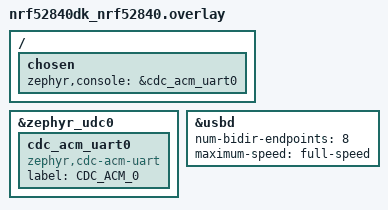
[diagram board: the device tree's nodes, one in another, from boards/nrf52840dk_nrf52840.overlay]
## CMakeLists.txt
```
# SPDX-License-Identifier: Apache-2.0

cmake_minimum_required(VERSION 3.20.0)

find_package(Zephyr REQUIRED HINTS $ENV{ZEPHYR_BASE})
project(usb_printer)

target_sources(app PRIVATE
  src/main.c
  src/printer_pcl.c
  src/printer_pjl.c
  src/printer_queue.c
  )

# Add include directory
target_include_directories(app PRIVATE
  ${CMAKE_CURRENT_SOURCE_DIR}/src
  )

# Generate version header
configure_file(
  ${CMAKE_CURRENT_SOURCE_DIR}/src/version.h.in
  ${CMAKE_CURRENT_BINARY_DIR}/include/generated/version.h
  )
```

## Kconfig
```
# Copyright (c) 2024 Nordic Semiconductor ASA
# SPDX-License-Identifier: Apache-2.0

source "Kconfig.zephyr"

config USB_PRINTER_SAMPLE_DEVICE_ID
	string "IEEE 1284 Device ID string"
	default "MFG:Zephyr;MDL:USB-Printer;CMD:PJL,PCL;CLS:PRINTER;DES:Zephyr USB Printer Sample;VER:1.0;"
	help
	  IEEE 1284 Device ID string reported by the printer.

config USB_PRINTER_SAMPLE_RING_BUF_SIZE
	int "Size of receive ring buffer"
	default 1024
	range 256 4096
	help
	  Size of the ring buffer used for receiving print data.

config USB_PRINTER_SAMPLE_PCL_SUPPORT
	bool "Enable PCL command support"
	default y
	help
	  Enable support for PCL printer commands.

config USB_PRINTER_SAMPLE_PJL_SUPPORT
	bool "Enable PJL job control"
	default y
	depends on USB_PRINTER_SAMPLE_PCL_SUPPORT
	help
	  Enable support for PJL job control commands.

config USB_PRINTER_SAMPLE_TEST_PAGE
	bool "Enable test page support"
	default y
	help
	  Enable built-in test page generation.

config USB_PRINTER_SAMPLE_SIMULATED_ERRORS
	bool "Enable error simulation"
	default y
	help
	  Enable simulated paper out errors for testing.

config USB_PRINTER_SAMPLE_JOB_QUEUE_SIZE
	int "Maximum number of queued print jobs"
	default 5
	range 1 20
	help
	  Maximum number of print jobs that can be queued.
	  Each job requires memory for tracking status.

config USB_PRINTER_SAMPLE_PJL_BUFFER_SIZE
	int "Size of PJL response buffer"
	default 256
	range 128 1024
	depends on USB_PRINTER_SAMPLE_PJL_SUPPORT
	help
	  Size of buffer used for PJL response generation.
```

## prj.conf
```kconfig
# Enable USB
CONFIG_USB_DEVICE_STACK=y
CONFIG_USB_DEVICE_DRIVER=y

# Enable USB Printer class
CONFIG_USB_DEVICE_PRINTER=y

# Sample configs
CONFIG_USB_PRINTER_SAMPLE_DEVICE_ID="MFG:Zephyr;MDL:USB-Printer;CMD:PJL,PCL;CLS:PRINTER;DES:Zephyr USB Printer Sample;VER:1.0;"
CONFIG_USB_PRINTER_SAMPLE_RING_BUF_SIZE=1024
CONFIG_USB_PRINTER_SAMPLE_PJL_BUFFER_SIZE=256
CONFIG_USB_PRINTER_SAMPLE_PCL_SUPPORT=y
CONFIG_USB_PRINTER_SAMPLE_PJL_SUPPORT=y
CONFIG_USB_PRINTER_SAMPLE_TEST_PAGE=y
CONFIG_USB_PRINTER_SAMPLE_JOB_QUEUE_SIZE=5
CONFIG_USB_PRINTER_SAMPLE_SIMULATED_ERRORS=y

# Logging
CONFIG_USB_DRIVER_LOG_LEVEL_INF=y
CONFIG_USB_DEVICE_LOG_LEVEL_INF=y
CONFIG_LOG=y
CONFIG_LOG_DEFAULT_LEVEL=3

# Threading
CONFIG_MULTITHREADING=y
CONFIG_NUM_PREEMPT_PRIORITIES=16
CONFIG_MAIN_STACK_SIZE=2048
CONFIG_HEAP_MEM_POOL_SIZE=4096

# Enable errno defines
CONFIG_ERRNO=y

# System clock configuration
CONFIG_SYS_CLOCK_TICKS_PER_SEC=1000

# Enable USB device stack next generation
CONFIG_USB_DEVICE_STACK_NEXT=y

# Enable USB device string descriptors
CONFIG_USB_DEVICE_STRING_DESC_MAX_LEN=64

# Enable USB composite device support
CONFIG_USB_COMPOSITE_DEVICE=y

# Enable USB device manufacturing string
CONFIG_USB_DEVICE_MANUFACTURER="Zephyr"
CONFIG_USB_DEVICE_PRODUCT="USB Printer"
CONFIG_USB_DEVICE_SN="0123456789AB"
```

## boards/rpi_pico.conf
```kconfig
# Increase USB buffer sizes for Pico
CONFIG_USB_DEVICE_BULK_EP_MPS=64
CONFIG_USB_PRINTER_SAMPLE_RING_BUF_SIZE=2048

# Optimize memory usage
CONFIG_HEAP_MEM_POOL_SIZE=2048
CONFIG_MAIN_STACK_SIZE=2048
CONFIG_USB_DEVICE_STACK_NEXT=y

# Enable USB logging for debugging
CONFIG_USB_DRIVER_LOG_LEVEL_INF=y
CONFIG_USB_DEVICE_LOG_LEVEL_INF=y
```

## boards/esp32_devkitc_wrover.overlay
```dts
/* Enable USB on ESP32-WROVER */

/ {
	chosen {
		zephyr,console = &uart0;
	};
};

&usb_serial {
	status = "okay";
};
```

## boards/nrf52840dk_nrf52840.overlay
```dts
/* Add USB support for nRF52840 DK */

/ {
	chosen {
		zephyr,console = &cdc_acm_uart0;
	};
};

&zephyr_udc0 {
	cdc_acm_uart0: cdc_acm_uart0 {
		compatible = "zephyr,cdc-acm-uart";
		label = "CDC_ACM_0";
	};
};

&usbd {
	status = "okay";
	num-bidir-endpoints = <8>;
	maximum-speed = "full-speed";
};
```

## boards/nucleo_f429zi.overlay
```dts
/* Enable USB on STM32F429 Nucleo */

/ {
	chosen {
		zephyr,console = &usart3;
	};
};

&usb {
	status = "okay";
	pinctrl-0 = <&usb_otg_fs_dm_pa11 &usb_otg_fs_dp_pa12>;
	pinctrl-names = "default";
};

&clk_hse {
	status = "okay";
	clock-frequency = <8000000>;
};
```

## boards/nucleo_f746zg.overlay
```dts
/* Enable USB on STM32 Nucleo boards */

&clk_hse {
    clock-frequency = <DT_FREQ_M(8)>;
    status = "okay";
};

&pll {
    div-m = <8>;
    mul-n = <336>;
    div-p = <2>;
    div-q = <7>;
    clocks = <&clk_hse>;
    status = "okay";
};

&rcc {
    clocks = <&pll>;
    clock-frequency = <DT_FREQ_M(168)>;
    ahb-prescaler = <1>;
    apb1-prescaler = <4>;
    apb2-prescaler = <2>;
};

&usbotg_fs {
    pinctrl-0 = <&usb_otg_fs_dm_pa11 &usb_otg_fs_dp_pa12>;
    pinctrl-names = "default";
    status = "okay";
};
```

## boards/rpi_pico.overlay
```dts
/* Enable USB on Raspberry Pi Pico */

/ {
	chosen {
		zephyr,console = &uart0;
	};
};

&usbd {
	status = "okay";
};

&uart0 {
	status = "okay";
	current-speed = <115200>;
};
```

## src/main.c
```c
/*
 * Copyright (c) 2024 Nordic Semiconductor ASA
 *
 * SPDX-License-Identifier: Apache-2.0
 */

#include <zephyr/kernel.h>
#include <zephyr/device.h>
#include <zephyr/logging/log.h>
#include <zephyr/usb/usb_device.h>
#include <zephyr/usb/class/usb_printer.h>
#include <zephyr/sys/ring_buffer.h>
#include <errno.h>
#include <zephyr/sys/byteorder.h>
#include <string.h>
#include "printer_pcl.h"
#include "printer_pjl.h"
#include "printer_queue.h"

LOG_MODULE_REGISTER(main);

/* Ring buffer for received data */
RING_BUF_DECLARE(printer_rx_buf, CONFIG_USB_PRINTER_SAMPLE_RING_BUF_SIZE);
K_MUTEX_DEFINE(printer_rx_mutex);

/* Semaphore to signal data reception */
K_SEM_DEFINE(printer_rx_sem, 0, 1);

/* Printer state tracking */
static struct pcl_parser_state pcl_parser;
static struct print_job *current_job;
static bool printer_paper_present = true;
static enum printer_state {
    PRINTER_READY,
    PRINTER_BUSY,
    PRINTER_ERROR,
    PRINTER_NO_PAPER
} current_state = PRINTER_READY;

/* PJL response buffer */
static char pjl_response[CONFIG_USB_PRINTER_SAMPLE_PJL_BUFFER_SIZE];

#if defined(CONFIG_USB_PRINTER_SAMPLE_TEST_PAGE)
/* Test page buffer */
static uint8_t test_page[TEST_PAGE_WIDTH * TEST_PAGE_HEIGHT];
static size_t test_page_len;
static bool test_page_pending;
#endif

static void update_printer_status(void)
{
    uint8_t status = USB_PRINTER_STATUS_SELECTED;

    switch (current_state) {
    case PRINTER_ERROR:
        status |= USB_PRINTER_STATUS_ERROR;
        break;
    case PRINTER_NO_PAPER:
        status |= USB_PRINTER_STATUS_ERROR | USB_PRINTER_STATUS_PAPER;
        break;
    default:
        break;
    }

    usb_printer_update_status(status);

    /* Send PJL status update if job active */
    if (current_job) {
        int len = pjl_generate_response(pjl_response, sizeof(pjl_response),
                                      PJL_USTATUS " DEVICE", current_job);
        if (len > 0) {
            usb_printer_send_data(pjl_response, len);
        }
    }
}

/* Job management */
static void start_print_job(void)
{
    if (current_job == NULL) {
        current_job = print_queue_get_next();
        if (current_job) {
            LOG_INF("Processing job %d (%s)", 
                    current_job->job_id, current_job->name);
            update_printer_status();
        }
    }
}

static void finish_current_job(bool success)
{
    if (current_job) {
        uint32_t duration = (k_uptime_get_32() - current_job->start_time) / 1000;
        
        if (success) {
            LOG_INF("Completed job %d (%s): %d pages in %d seconds",
                    current_job->job_id, current_job->name,
                    current_job->pages_printed, duration);
            print_queue_update_state(current_job->job_id,
                                   JOB_STATE_COMPLETED, 0);
        } else {
            LOG_WRN("Failed job %d (%s) after %d pages",
                    current_job->job_id, current_job->name,
                    current_job->pages_printed);
            print_queue_update_state(current_job->job_id,
                                   JOB_STATE_FAILED, current_state);
        }

        /* Send final job status */
        int len = pjl_generate_response(pjl_response, sizeof(pjl_response),
                                      PJL_USTATUS " JOB", current_job);
        if (len > 0) {
            usb_printer_send_data(pjl_response, len);
        }

        current_job = NULL;
        
        /* Clean up completed jobs */
        print_queue_cleanup();
        
        /* Start next job if available */
        start_print_job();
    }
}

#if defined(CONFIG_USB_PRINTER_SAMPLE_SIMULATED_ERRORS)
static void toggle_paper_sensor(void)
{
    printer_paper_present = !printer_paper_present;
    
    if (!printer_paper_present) {
        current_state = PRINTER_NO_PAPER;
        LOG_INF("Paper out");
        
        /* Fail current job if active */
        if (current_job) {
            finish_current_job(false);
        }
    } else {
        current_state = PRINTER_READY;
        LOG_INF("Paper loaded");
        
        /* Start next job if available */
        start_print_job();
    }
    
    update_printer_status();
}
#endif

static void printer_status_changed(bool configured)
{
    if (configured) {
        LOG_INF("USB printer device configured");
        pcl_parser_init(&pcl_parser);
        print_queue_init();
        update_printer_status();
    } else {
        LOG_INF("USB printer device disconnected");
        if (current_job) {
            finish_current_job(false);
        }
        k_mutex_lock(&printer_rx_mutex, K_FOREVER);
        ring_buf_reset(&printer_rx_buf);
        k_mutex_unlock(&printer_rx_mutex);
    }
}

static int printer_class_handle_request(struct usb_setup_packet *setup,
                                      int32_t *len, uint8_t **data)
{
#if defined(CONFIG_USB_PRINTER_SAMPLE_TEST_PAGE)
    /* Check if this is a test page request (vendor-specific) */
    if (setup->bRequest == 0xFF && setup->wValue == 0x00) {
        if (!test_page_pending) {
            struct print_job *job = pcl_start_print_job();
            if (job) {
                strncpy(job->name, "Test Page", sizeof(job->name));
                if (print_queue_add_job(job)) {
                    pcl_generate_test_page(test_page, &test_page_len);
                    test_page_pending = true;
                    start_print_job();
                } else {
                    k_free(job);
                    return -EBUSY;
                }
            }
        }
        return 0;
    }
#endif
    return -ENOTSUP;
}

/* Process received data */
static void process_received_data(const uint8_t *data, size_t len)
{
#if defined(CONFIG_USB_PRINTER_SAMPLE_PJL_SUPPORT)
    /* Check for PJL commands first */
    if (pjl_process_command(current_job, data, len)) {
        /* Generate PJL response if needed */
        int resp_len = pjl_generate_response(pjl_response,
                                           sizeof(pjl_response),
                                           (const char *)data,
                                           current_job);
        if (resp_len > 0) {
            usb_printer_send_data(pjl_response, resp_len);
        }
        return;
    }
#endif

#if defined(CONFIG_USB_PRINTER_SAMPLE_PCL_SUPPORT)
    /* Process PCL if not PJL */
    pcl_process_command(&pcl_parser, current_job, data, len);
#else
    /* Raw text mode - just count form feeds */
    for (size_t i = 0; i < len; i++) {
        if (data[i] == PCL_FF && current_job) {
            current_job->pages_printed++;
            LOG_INF("Page %d printed", current_job->pages_printed);
        }
    }
#endif
}

/* Data received callback */
static void printer_data_received(const uint8_t *data, size_t len)
{
    if (!data || !len) {
        return;
    }

    /* Reject data if we're in an error state */
    if (current_state == PRINTER_ERROR || current_state == PRINTER_NO_PAPER) {
        LOG_WRN("Printer not ready, data rejected");
        return;
    }

    /* Start a new print job if needed */
    if (!current_job) {
        struct print_job *job = pcl_start_print_job();
        if (job) {
            snprintf(job->name, sizeof(job->name),
                    "Job-%d", job->job_id);
            if (print_queue_add_job(job)) {
                start_print_job();
            } else {
                k_free(job);
                return;
            }
        }
    }

    k_mutex_lock(&printer_rx_mutex, K_FOREVER);
    
    uint32_t written = ring_buf_put(&printer_rx_buf, data, len);
    if (written < len) {
        LOG_WRN("Buffer full, dropped %d bytes", len - written);
    }
    
    k_mutex_unlock(&printer_rx_mutex);
    k_sem_give(&printer_rx_sem);
}

/* USB Printer configuration */
static const struct usb_printer_config printer_config = {
    .status_cb = printer_status_changed,
    .class_handler = printer_class_handle_request,
    .device_id = CONFIG_USB_PRINTER_SAMPLE_DEVICE_ID,
    .data_received = printer_data_received,
};

#if defined(CONFIG_USB_PRINTER_SAMPLE_TEST_PAGE)
/* Process test page if pending */
static void process_test_page(void)
{
    if (test_page_pending && current_job) {
        int ret = usb_printer_send_data(test_page, test_page_len);
        if (ret > 0) {
            LOG_INF("Test page sent");
            current_job->pages_printed++;
            finish_current_job(true);
        }
        test_page_pending = false;
    }
}
#endif

/* Print data processing task */
static void printer_task(void)
{
    uint8_t buf[64];
    uint32_t bytes_read;

    while (1) {
        /* Wait for data */
        k_sem_take(&printer_rx_sem, K_FOREVER);

#if defined(CONFIG_USB_PRINTER_SAMPLE_TEST_PAGE)
        /* Process test page if pending */
        process_test_page();
#endif

        k_mutex_lock(&printer_rx_mutex, K_FOREVER);
        bytes_read = ring_buf_get(&printer_rx_buf, buf, sizeof(buf));
        k_mutex_unlock(&printer_rx_mutex);

        if (bytes_read > 0) {
            /* Process received print data */
            LOG_HEXDUMP_DBG(buf, bytes_read, "Received print data:");
            
            /* Simulate busy state during processing */
            current_state = PRINTER_BUSY;
            update_printer_status();
            
            /* Process received data */
            process_received_data(buf, bytes_read);
            
            /* Check if job complete */
            if (current_job && current_job->pages_printed > 0 &&
                ring_buf_is_empty(&printer_rx_buf)) {
                finish_current_job(true);
            }
            
            /* Return to ready if no errors occurred */
            if (current_state == PRINTER_BUSY) {
                current_state = PRINTER_READY;
                update_printer_status();
            }
            
#if defined(CONFIG_USB_PRINTER_SAMPLE_SIMULATED_ERRORS)
            /* Simulate paper out every 10 pages */
            if (current_job && (current_job->pages_printed % 10) == 0) {
                toggle_paper_sensor();
            }
#endif
            
            /* Simulate processing time */
            k_sleep(K_MSEC(100));
        }
    }
}

K_THREAD_DEFINE(printer_task_id, 2048, printer_task, NULL, NULL, NULL,
                K_PRIO_PREEMPT(8), 0, 0);

void main(void)
{
    int ret;

    LOG_INF("Starting USB printer sample");

    ret = usb_printer_init(&printer_config);
    if (ret < 0) {
        LOG_ERR("Failed to initialize USB printer: %d", ret);
        return;
    }

    LOG_INF("USB printer initialized");
}
```

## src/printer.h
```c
#ifndef USB_PRINTER_H
#define USB_PRINTER_H

#include <zephyr/kernel.h>
#include <zephyr/usb/usb_device.h>
#include <zephyr/usb/class/usb_printer.h>

/* Common printer commands */
#define PCL_ESC     0x1B    /* ESC character */
#define PCL_FF      0x0C    /* Form Feed */
#define PCL_LF      0x0A    /* Line Feed */
#define PCL_CR      0x0D    /* Carriage Return */

/* Test page dimensions */
#define TEST_PAGE_WIDTH  80
#define TEST_PAGE_HEIGHT 60

/* Print job states */
enum job_state {
    JOB_STATE_PENDING = 0,
    JOB_STATE_PRINTING,
    JOB_STATE_COMPLETED,
    JOB_STATE_CANCELLED,
    JOB_STATE_FAILED
};

/* Print job structure */
struct print_job {
    uint32_t job_id;
    char name[32];
    enum job_state state;
    uint32_t error_code;
    uint32_t pages_printed;
    uint32_t start_time;
    struct print_job *next;
};

#endif /* USB_PRINTER_H */
```

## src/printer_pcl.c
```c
/*
 * Copyright (c) 2024 Nordic Semiconductor ASA
 *
 * SPDX-License-Identifier: Apache-2.0
 */

#include <zephyr/kernel.h>
#include <string.h>
#include "printer_pcl.h"

#include <zephyr/logging/log.h>
LOG_MODULE_REGISTER(printer_pcl, CONFIG_USB_DEVICE_LOG_LEVEL);

static uint32_t next_job_id;

void pcl_parser_init(struct pcl_parser_state *parser)
{
    memset(parser, 0, sizeof(*parser));
}

#if defined(CONFIG_USB_PRINTER_SAMPLE_PCL_SUPPORT)
static void process_escape_sequence(struct pcl_parser_state *parser,
                                  struct print_job *job)
{
    /* Skip ESC character */
    if (parser->cmd_pos < 2) {
        return;
    }

    switch (parser->cmd_buf[1]) {
    case 'E':  /* Printer reset */
        LOG_INF("PCL: Printer reset");
        parser->landscape = false;
        parser->manual_feed = false;
        break;

    case '&':  /* PCL parameterized command */
        if (parser->cmd_pos < 4) {
            return;
        }
        if (parser->cmd_buf[2] == 'l') {  /* Logical page */
            switch (parser->cmd_buf[3]) {
            case '0':  /* Portrait orientation */
                if (parser->cmd_buf[4] == 'O') {
                    LOG_INF("PCL: Portrait orientation");
                    parser->landscape = false;
                    if (job) {
                        job->landscape = false;
                    }
                }
                break;
            case '1':  /* Landscape orientation */
                if (parser->cmd_buf[4] == 'O') {
                    LOG_INF("PCL: Landscape orientation");
                    parser->landscape = true;
                    if (job) {
                        job->landscape = true;
                    }
                }
                break;
            case '1':  /* Media source - Tray 1 */
                if (parser->cmd_buf[4] == 'H') {
                    LOG_INF("PCL: Paper from Tray 1");
                    parser->manual_feed = false;
                    if (job) {
                        job->manual_feed = false;
                    }
                }
                break;
            case '2':  /* Media source - Manual */
                if (parser->cmd_buf[4] == 'H') {
                    LOG_INF("PCL: Manual paper feed");
                    parser->manual_feed = true;
                    if (job) {
                        job->manual_feed = true;
                    }
                }
                break;
            }
        }
        break;

    case '(':  /* Font selection */
        LOG_INF("PCL: Font selection command");
        break;
    }
}
#endif /* CONFIG_USB_PRINTER_SAMPLE_PCL_SUPPORT */

void pcl_process_command(struct pcl_parser_state *parser,
                        struct print_job *job,
                        const uint8_t *data,
                        size_t len)
{
    for (size_t i = 0; i < len; i++) {
        uint8_t ch = data[i];

#if defined(CONFIG_USB_PRINTER_SAMPLE_PCL_SUPPORT)
        if (parser->in_escape) {
            if (parser->cmd_pos < sizeof(parser->cmd_buf)) {
                parser->cmd_buf[parser->cmd_pos++] = ch;
            }
            /* Look for command terminator */
            if ((ch >= 'A' && ch <= 'Z') || (ch >= 'a' && ch <= 'z')) {
                process_escape_sequence(parser, job);
                parser->in_escape = false;
                parser->cmd_pos = 0;
            }
        } else {
            if (ch == PCL_ESC) {
                parser->in_escape = true;
                parser->cmd_pos = 0;
                parser->cmd_buf[parser->cmd_pos++] = ch;
            } else if (ch == PCL_FF) {
                /* Form feed - page complete */
                if (job) {
                    job->pages_printed++;
                    LOG_INF("Page %d printed", job->pages_printed);
                }
            }
        }
#else
        /* Without PCL support, just count pages on form feeds */
        if (ch == PCL_FF && job) {
            job->pages_printed++;
            LOG_INF("Page %d printed", job->pages_printed);
        }
#endif /* CONFIG_USB_PRINTER_SAMPLE_PCL_SUPPORT */
    }
}

#if defined(CONFIG_USB_PRINTER_SAMPLE_TEST_PAGE)
void pcl_generate_test_page(uint8_t *buffer, size_t *len)
{
    char *pos = buffer;
    int remaining = TEST_PAGE_WIDTH * TEST_PAGE_HEIGHT;

#if defined(CONFIG_USB_PRINTER_SAMPLE_PCL_SUPPORT)
    /* Reset printer and set format with PCL */
    pos += snprintf(pos, remaining, "%s%s%s",
                   PCL_RESET, PCL_PORTRAIT, PCL_FONT_COURIER);
#endif

    /* Header */
    pos += snprintf(pos, remaining,
                   "\r\n\r\n"
                   "    USB Printer Test Page\r\n"
                   "    ===================\r\n\r\n");

    /* Printer information */
    pos += snprintf(pos, remaining,
                   "Model: Virtual PCL Printer\r\n"
                   "Firmware: Zephyr RTOS USB Printer Sample\r\n"
                   "Status: Ready\r\n\r\n");

    /* Print capabilities */
    pos += snprintf(pos, remaining,
                   "Supported Features:\r\n"
#if defined(CONFIG_USB_PRINTER_SAMPLE_PCL_SUPPORT)
                   "- PCL command processing\r\n"
                   "- Portrait/Landscape modes\r\n"
                   "- Multiple paper sources\r\n"
#else
                   "- Raw text printing\r\n"
#endif
                   "- Job tracking\r\n"
                   "- Status reporting\r\n\r\n");

    /* Test patterns */
    pos += snprintf(pos, remaining,
                   "Print Test Pattern:\r\n"
                   "==================\r\n\r\n");

    /* Character test */
    for (char c = 33; c <= 126; c++) {
        *pos++ = c;
        if ((c - 32) % TEST_PAGE_WIDTH == 0) {
            *pos++ = '\r';
            *pos++ = '\n';
        }
    }

    /* Form feed at end of page */
    *pos++ = PCL_FF;

    *len = pos - (char *)buffer;
}
#endif /* CONFIG_USB_PRINTER_SAMPLE_TEST_PAGE */

struct print_job *pcl_start_print_job(void)
{
    struct print_job *job = k_malloc(sizeof(struct print_job));
    
    if (job) {
        memset(job, 0, sizeof(*job));
        job->job_id = ++next_job_id;
        job->start_time = k_uptime_get_32();
    }

    return job;
}
```

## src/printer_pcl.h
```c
/*
 * Copyright (c) 2024 Nordic Semiconductor ASA
 *
 * SPDX-License-Identifier: Apache-2.0
 */

#ifndef PRINTER_PCL_H_
#define PRINTER_PCL_H_

#include <stdint.h>
#include <stdbool.h>
#include <zephyr/kernel.h>

/*
 * PCL Command Reference
 * ====================
 * 
 * Reset:
 * ESC E - Printer reset, clear margins, select default font
 * 
 * Page Control:
 * ESC&l0O - Select portrait orientation
 * ESC&l1O - Select landscape orientation
 * ESC&l1H - Select paper from Tray 1
 * ESC&l2H - Select manual paper feed
 * FF     - Form feed (0x0C)
 * CR     - Carriage return (0x0D)
 * LF     - Line feed (0x0A)
 * 
 * Font Selection:
 * ESC(s#P - Set pitch (# = chars per inch)
 * ESC(s#H - Set height (points)
 * ESC(s#V - Set style (0=upright, 1=italic)
 * ESC(s#S - Set stroke weight (0=normal, 3=bold)
 */

/* PCL command characters */
#define PCL_ESC             0x1B    /* ESC character */
#define PCL_FF              0x0C    /* Form Feed */
#define PCL_CR              0x0D    /* Carriage Return */
#define PCL_LF              0x0A    /* Line Feed */

/* PCL command sequences */
#define PCL_RESET           "\x1BE"
#define PCL_PORTRAIT        "\x1B&l0O"
#define PCL_LANDSCAPE       "\x1B&l1O"
#define PCL_FONT_COURIER    "\x1B(s0p12h0s0b4099T"
#define PCL_FONT_LINE       "\x1B(s1p12v0s0b4099T"
#define PCL_MEDIA_TRAY1     "\x1B&l1H"
#define PCL_MEDIA_MANUAL    "\x1B&l2H"

/* Print job information */
struct print_job {
    uint32_t job_id;
    uint32_t pages_total;
    uint32_t pages_printed;
    bool landscape;
    bool manual_feed;
    uint32_t start_time;
    char name[32];           /* Job name from PJL */
};

/* PCL parser state */
struct pcl_parser_state {
    bool in_escape;
    uint8_t cmd_buf[32];
    uint8_t cmd_pos;
    bool landscape;
    bool manual_feed;
};

/* Test page configuration */
#if defined(CONFIG_USB_PRINTER_SAMPLE_TEST_PAGE)
#define TEST_PAGE_WIDTH     80
#define TEST_PAGE_HEIGHT    60
#endif

/**
 * @brief Initialize PCL parser state
 *
 * @param parser Pointer to parser state structure
 */
void pcl_parser_init(struct pcl_parser_state *parser);

/**
 * @brief Process PCL commands in received data
 *
 * Processes PCL escape sequences and updates printer state.
 * If CONFIG_USB_PRINTER_SAMPLE_PCL_SUPPORT is disabled,
 * treats all data as raw text.
 *
 * @param parser PCL parser state
 * @param job Current print job info
 * @param data Received data buffer
 * @param len Length of received data
 */
void pcl_process_command(struct pcl_parser_state *parser,
                        struct print_job *job,
                        const uint8_t *data,
                        size_t len);

#if defined(CONFIG_USB_PRINTER_SAMPLE_TEST_PAGE)
/**
 * @brief Generate test page content
 *
 * @param buffer Buffer to store test page data
 * @param len Pointer to store length of generated data
 */
void pcl_generate_test_page(uint8_t *buffer, size_t *len);
#endif

/**
 * @brief Start a new print job
 *
 * @return Pointer to new print job structure, or NULL if allocation failed
 */
struct print_job *pcl_start_print_job(void);

#endif /* PRINTER_PCL_H_ */
```

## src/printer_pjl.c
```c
/*
 * Copyright (c) 2024 Nordic Semiconductor ASA
 *
 * SPDX-License-Identifier: Apache-2.0
 */

#include <zephyr/kernel.h>
#include <string.h>
#include "printer_pjl.h"

#include <zephyr/logging/log.h>
LOG_MODULE_REGISTER(printer_pjl, CONFIG_USB_DEVICE_LOG_LEVEL);

/* Command buffer for parsing */
static char cmd_buffer[128];

/* Parse PJL command string */
static const char *pjl_parse_command(const uint8_t *data, size_t len)
{
    /* Look for PJL prefix */
    if (len < strlen(PJL_PREFIX)) {
        return NULL;
    }

    if (memcmp(data, PJL_PREFIX, strlen(PJL_PREFIX)) != 0) {
        return NULL;
    }

    /* Look for @PJL marker */
    const char *cmd = strstr((const char *)data, PJL_ENTER);
    if (!cmd) {
        return NULL;
    }

    /* Skip @PJL and any whitespace */
    cmd += strlen(PJL_ENTER);
    while (*cmd == ' ') {
        cmd++;
    }

    /* Copy command to buffer for parsing */
    strncpy(cmd_buffer, cmd, sizeof(cmd_buffer) - 1);
    cmd_buffer[sizeof(cmd_buffer) - 1] = '\0';

    /* Strip EOL */
    char *eol = strstr(cmd_buffer, PJL_EOL);
    if (eol) {
        *eol = '\0';
    }

    return cmd_buffer;
}

bool pjl_process_command(struct print_job *job,
                        const uint8_t *data,
                        size_t len)
{
    const char *cmd = pjl_parse_command(data, len);
    if (!cmd) {
        return false;
    }

    LOG_DBG("PJL command: %s", cmd);

    if (strncmp(cmd, PJL_JOB, strlen(PJL_JOB)) == 0) {
        /* Job start command */
        if (job) {
            /* Extract job name if present */
            const char *name = strstr(cmd, "NAME=");
            if (name) {
                name += 5; /* Skip "NAME=" */
                if (*name == '"') {
                    name++; /* Skip quote */
                    strncpy(job->name, name, sizeof(job->name) - 1);
                    /* Strip end quote if present */
                    char *quote = strchr(job->name, '"');
                    if (quote) {
                        *quote = '\0';
                    }
                }
            }
            LOG_INF("PJL job start: %s", job->name);
        }
        return true;
    }

    if (strncmp(cmd, PJL_EOJ, strlen(PJL_EOJ)) == 0) {
        /* Job end command */
        if (job) {
            LOG_INF("PJL job end: %s, %d pages", 
                   job->name, job->pages_printed);
        }
        return true;
    }

    if (strncmp(cmd, PJL_ECHO, strlen(PJL_ECHO)) == 0) {
        /* Echo command - will be handled by response generator */
        return true;
    }

    if (strncmp(cmd, PJL_INFO, strlen(PJL_INFO)) == 0) {
        /* Information request - will be handled by response generator */
        return true;
    }

    if (strncmp(cmd, PJL_USTATUS, strlen(PJL_USTATUS)) == 0) {
        /* Status update request - will be handled by response generator */
        return true;
    }

    return false;
}

int pjl_generate_response(char *buffer,
                         size_t size,
                         const char *command,
                         const struct print_job *job)
{
    int len = 0;

    /* Add PJL prefix */
    len += snprintf(buffer + len, size - len, "%s%s", PJL_PREFIX, PJL_EOL);

    if (strncmp(command, PJL_ECHO, strlen(PJL_ECHO)) == 0) {
        /* Echo the command back */
        len += snprintf(buffer + len, size - len, "%s%s", command, PJL_EOL);
    }
    else if (strncmp(command, PJL_INFO, strlen(PJL_INFO)) == 0) {
        /* Return printer information */
        len += snprintf(buffer + len, size - len,
                       "@PJL INFO ID%s"
                       "\"Zephyr USB Printer Sample v1.0\"%s",
                       PJL_EOL, PJL_EOL);
    }
    else if (strncmp(command, PJL_USTATUS, strlen(PJL_USTATUS)) == 0) {
        /* Return printer status */
        if (job) {
            len += snprintf(buffer + len, size - len,
                          "@PJL USTATUS DEVICE%s"
                          "CODE=10001%s"  /* Printer ready */
                          "DISPLAY=\"Ready\"%s"
                          "ONLINE=TRUE%s",
                          PJL_EOL, PJL_EOL, PJL_EOL, PJL_EOL);
        } else {
            len += snprintf(buffer + len, size - len,
                          "@PJL USTATUS DEVICE%s"
                          "CODE=10000%s"  /* Printer idle */
                          "DISPLAY=\"Idle\"%s"
                          "ONLINE=TRUE%s",
                          PJL_EOL, PJL_EOL, PJL_EOL, PJL_EOL);
        }
    }

    /* Add universal exit language */
    len += snprintf(buffer + len, size - len, "%s", PJL_PREFIX);

    return len;
}
```

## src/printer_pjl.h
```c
/*
 * Copyright (c) 2024 Nordic Semiconductor ASA
 *
 * SPDX-License-Identifier: Apache-2.0
 */

#ifndef PRINTER_PJL_H_
#define PRINTER_PJL_H_

#include <stdint.h>
#include <stdbool.h>
#include "printer_pcl.h"

/* PJL command markers */
#define PJL_PREFIX      "\x1B%-12345X"  /* Universal Exit Language */
#define PJL_ENTER      "@PJL"           /* Enter PJL mode */
#define PJL_EOL        "\r\n"           /* PJL line ending */

/* PJL commands */
#define PJL_ECHO       "ECHO"
#define PJL_INFO       "INFO"
#define PJL_USTATUS    "USTATUS"
#define PJL_JOB        "JOB"
#define PJL_EOJ        "EOJ"

/* PJL status variables */
#define PJL_STATUS_DEVICE      "DEVICE"
#define PJL_STATUS_JOB        "JOB"
#define PJL_STATUS_PAGE       "PAGE"
#define PJL_STATUS_TIMED      "TIMED"

/* PJL job information */
struct pjl_job_info {
    char name[32];        /* Job name */
    char user[32];        /* User name */
    uint32_t start_time;  /* Job start time */
    uint32_t pages;       /* Pages in job */
};

/**
 * @brief Process PJL command sequence
 *
 * @param job Current print job info
 * @param data Command data
 * @param len Command length 
 * @return true if command was a PJL command
 */
bool pjl_process_command(struct print_job *job,
                        const uint8_t *data,
                        size_t len);

/**
 * @brief Generate PJL response
 *
 * @param buffer Buffer to store response
 * @param size Size of buffer
 * @param command PJL command that was received
 * @param job Current print job
 * @return Length of response or negative error
 */
int pjl_generate_response(char *buffer,
                         size_t size,
                         const char *command,
                         const struct print_job *job);

#endif /* PRINTER_PJL_H_ */
```

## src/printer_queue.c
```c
/*
 * Copyright (c) 2024 Nordic Semiconductor ASA
 *
 * SPDX-License-Identifier: Apache-2.0
 */

#include <zephyr/kernel.h>
#include <string.h>
#include "printer_queue.h"

#include <zephyr/logging/log.h>
LOG_MODULE_REGISTER(printer_queue, CONFIG_USB_DEVICE_LOG_LEVEL);

/* Queue of print jobs */
static struct print_job_info job_queue[CONFIG_USB_PRINTER_SAMPLE_JOB_QUEUE_SIZE];
static uint32_t queue_head;  /* Index of first job */
static uint32_t queue_tail;  /* Index for adding new jobs */
static uint32_t queue_count; /* Number of jobs in queue */

/* Mutex to protect queue access */
K_MUTEX_DEFINE(queue_mutex);

void print_queue_init(void)
{
    k_mutex_lock(&queue_mutex, K_FOREVER);
    memset(job_queue, 0, sizeof(job_queue));
    queue_head = 0;
    queue_tail = 0;
    queue_count = 0;
    k_mutex_unlock(&queue_mutex);
}

bool print_queue_add_job(struct print_job *job)
{
    bool added = false;

    k_mutex_lock(&queue_mutex, K_FOREVER);

    if (queue_count < CONFIG_USB_PRINTER_SAMPLE_JOB_QUEUE_SIZE) {
        /* Copy job data and initialize extended info */
        memcpy(&job_queue[queue_tail].job, job, sizeof(struct print_job));
        job_queue[queue_tail].state = JOB_STATE_PENDING;
        job_queue[queue_tail].error_code = 0;
        
        /* Update tail and count */
        queue_tail = (queue_tail + 1) % CONFIG_USB_PRINTER_SAMPLE_JOB_QUEUE_SIZE;
        queue_count++;
        
        LOG_INF("Added job %d to queue, %d jobs total",
                job->job_id, queue_count);
        added = true;
    } else {
        LOG_WRN("Job queue full, cannot add job %d", job->job_id);
    }

    k_mutex_unlock(&queue_mutex);
    return added;
}

struct print_job *print_queue_get_next(void)
{
    struct print_job *next_job = NULL;

    k_mutex_lock(&queue_mutex, K_FOREVER);

    if (queue_count > 0) {
        /* Get first pending job */
        for (uint32_t i = 0; i < CONFIG_USB_PRINTER_SAMPLE_JOB_QUEUE_SIZE; i++) {
            uint32_t idx = (queue_head + i) % CONFIG_USB_PRINTER_SAMPLE_JOB_QUEUE_SIZE;
            if (job_queue[idx].state == JOB_STATE_PENDING) {
                job_queue[idx].state = JOB_STATE_ACTIVE;
                next_job = &job_queue[idx].job;
                LOG_INF("Starting job %d", next_job->job_id);
                break;
            }
        }
    }

    k_mutex_unlock(&queue_mutex);
    return next_job;
}

bool print_queue_update_state(uint32_t job_id,
                            enum print_job_state state,
                            uint32_t error_code)
{
    bool updated = false;

    k_mutex_lock(&queue_mutex, K_FOREVER);

    /* Find job in queue */
    for (uint32_t i = 0; i < CONFIG_USB_PRINTER_SAMPLE_JOB_QUEUE_SIZE; i++) {
        if (job_queue[i].job.job_id == job_id) {
            job_queue[i].state = state;
            job_queue[i].error_code = error_code;
            
            LOG_INF("Job %d state changed to %d", job_id, state);
            updated = true;
            break;
        }
    }

    k_mutex_unlock(&queue_mutex);
    return updated;
}

const struct print_job_info *print_queue_get_info(uint32_t job_id)
{
    const struct print_job_info *info = NULL;

    k_mutex_lock(&queue_mutex, K_FOREVER);

    /* Find job in queue */
    for (uint32_t i = 0; i < CONFIG_USB_PRINTER_SAMPLE_JOB_QUEUE_SIZE; i++) {
        if (job_queue[i].job.job_id == job_id) {
            info = &job_queue[i];
            break;
        }
    }

    k_mutex_unlock(&queue_mutex);
    return info;
}

bool print_queue_cancel_job(uint32_t job_id)
{
    bool cancelled = false;

    k_mutex_lock(&queue_mutex, K_FOREVER);

    /* Find job in queue */
    for (uint32_t i = 0; i < CONFIG_USB_PRINTER_SAMPLE_JOB_QUEUE_SIZE; i++) {
        if (job_queue[i].job.job_id == job_id &&
            (job_queue[i].state == JOB_STATE_PENDING ||
             job_queue[i].state == JOB_STATE_ACTIVE)) {
            
            job_queue[i].state = JOB_STATE_CANCELLED;
            LOG_INF("Job %d cancelled", job_id);
            cancelled = true;
            break;
        }
    }

    k_mutex_unlock(&queue_mutex);
    return cancelled;
}

uint32_t print_queue_get_count(void)
{
    k_mutex_lock(&queue_mutex, K_FOREVER);
    uint32_t count = queue_count;
    k_mutex_unlock(&queue_mutex);
    return count;
}

void print_queue_cleanup(void)
{
    k_mutex_lock(&queue_mutex, K_FOREVER);

    /* Remove completed/failed/cancelled jobs */
    while (queue_count > 0 &&
           (job_queue[queue_head].state == JOB_STATE_COMPLETED ||
            job_queue[queue_head].state == JOB_STATE_FAILED ||
            job_queue[queue_head].state == JOB_STATE_CANCELLED)) {
        
        LOG_INF("Removing job %d from queue",
                job_queue[queue_head].job.job_id);
        
        /* Clear job data */
        memset(&job_queue[queue_head], 0, sizeof(struct print_job_info));
        
        /* Update head and count */
        queue_head = (queue_head + 1) % CONFIG_USB_PRINTER_SAMPLE_JOB_QUEUE_SIZE;
        queue_count--;
    }

    k_mutex_unlock(&queue_mutex);
}
```

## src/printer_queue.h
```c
/*
 * Copyright (c) 2024 Nordic Semiconductor ASA
 *
 * SPDX-License-Identifier: Apache-2.0
 */

#ifndef PRINTER_QUEUE_H_
#define PRINTER_QUEUE_H_

#include <stdint.h>
#include <stdbool.h>
#include "printer_pcl.h"

/* Print job states */
enum print_job_state {
    JOB_STATE_PENDING,   /* Job waiting to be processed */
    JOB_STATE_ACTIVE,    /* Job currently printing */
    JOB_STATE_COMPLETED, /* Job finished successfully */
    JOB_STATE_FAILED,    /* Job failed (error occurred) */
    JOB_STATE_CANCELLED  /* Job was cancelled */
};

/* Extended job information */
struct print_job_info {
    struct print_job job;         /* Base job information */
    enum print_job_state state;   /* Current job state */
    uint32_t error_code;         /* Error code if failed */
    void *next;                  /* Next job in queue */
};

/**
 * @brief Initialize the print job queue
 */
void print_queue_init(void);

/**
 * @brief Add a job to the print queue
 *
 * @param job Job to add to queue
 * @return true if job was queued, false if queue is full
 */
bool print_queue_add_job(struct print_job *job);

/**
 * @brief Get the next job from the queue
 *
 * @return Pointer to next job or NULL if queue empty
 */
struct print_job *print_queue_get_next(void);

/**
 * @brief Update job state
 *
 * @param job_id ID of job to update
 * @param state New job state
 * @param error_code Error code if job failed
 * @return true if job was found and updated
 */
bool print_queue_update_state(uint32_t job_id,
                            enum print_job_state state,
                            uint32_t error_code);

/**
 * @brief Get information about a specific job
 *
 * @param job_id ID of job to query
 * @return Pointer to job info or NULL if not found
 */
const struct print_job_info *print_queue_get_info(uint32_t job_id);

/**
 * @brief Cancel a pending or active job
 *
 * @param job_id ID of job to cancel
 * @return true if job was found and cancelled
 */
bool print_queue_cancel_job(uint32_t job_id);

/**
 * @brief Get number of jobs in queue
 *
 * @return Number of jobs currently in queue
 */
uint32_t print_queue_get_count(void);

/**
 * @brief Clean up completed/failed jobs
 *
 * Removes jobs that have been completed or failed from the queue
 */
void print_queue_cleanup(void);

#endif /* PRINTER_QUEUE_H_ */
```
